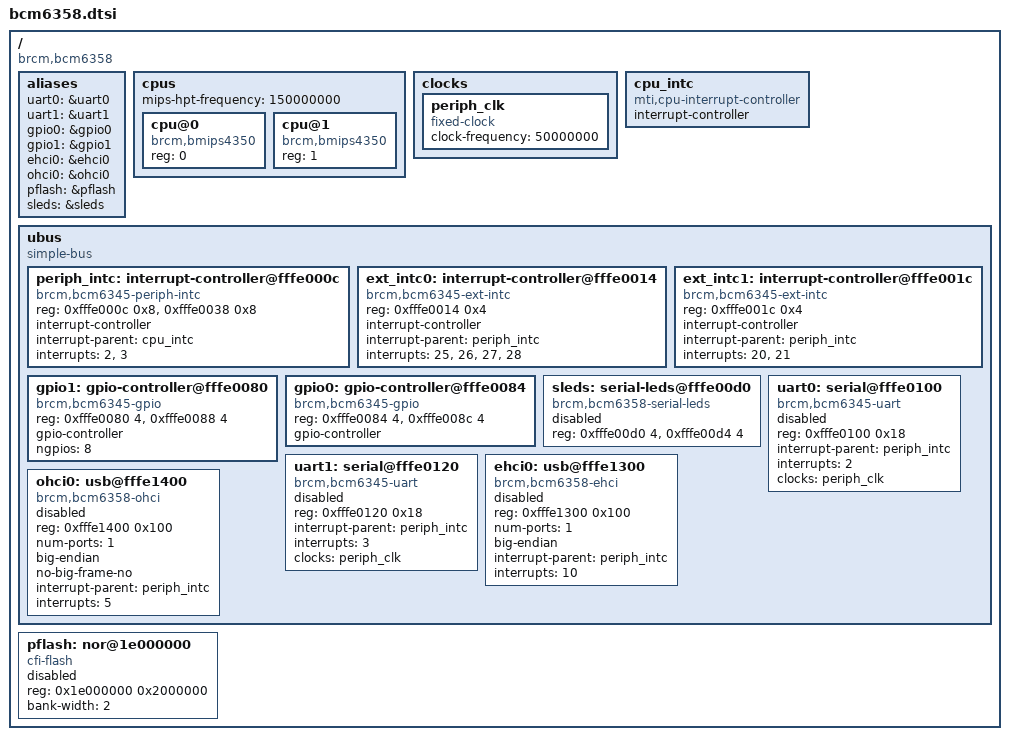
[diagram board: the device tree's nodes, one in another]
/ {
	#address-cells = <1>;
	#size-cells = <1>;
	compatible = "brcm,bcm6358";

	aliases {
		uart0 = &uart0;
		uart1 = &uart1;
		gpio0 = &gpio0;
		gpio1 = &gpio1;
		ehci0 = &ehci0;
		ohci0 = &ohci0;
		pflash = &pflash;
		sleds = &sleds;
	};

	cpus {
		#address-cells = <1>;
		#size-cells = <0>;

		mips-hpt-frequency = <150000000>;

		cpu@0 {
			compatible = "brcm,bmips4350";
			device_type = "cpu";
			reg = <0>;
		};

		cpu@1 {
			compatible = "brcm,bmips4350";
			device_type = "cpu";
			reg = <1>;
		};
	};

	clocks {
		periph_clk: periph_clk {
			compatible = "fixed-clock";
			#clock-cells = <0>;
			clock-frequency = <50000000>;
		};
	};

	cpu_intc: cpu_intc {
		#address-cells = <0>;
		compatible = "mti,cpu-interrupt-controller";

		interrupt-controller;
		#interrupt-cells = <1>;
	};

	ubus {
		#address-cells = <1>;
		#size-cells = <1>;

		compatible = "simple-bus";
		ranges;

		periph_intc: interrupt-controller@fffe000c {
			compatible = "brcm,bcm6345-periph-intc";
			reg = <0xfffe000c 0x8>,
			      <0xfffe0038 0x8>;

			interrupt-controller;
			#interrupt-cells = <1>;

			interrupt-parent = <&cpu_intc>;
			interrupts = <2>, <3>;
		};

		ext_intc0: interrupt-controller@fffe0014 {
			compatible = "brcm,bcm6345-ext-intc";
			reg = <0xfffe0014 0x4>;

			interrupt-controller;
			#interrupt-cells = <2>;

			interrupt-parent = <&periph_intc>;
			interrupts = <25>, <26>, <27>, <28>;
		};

		ext_intc1: interrupt-controller@fffe001c {
			compatible = "brcm,bcm6345-ext-intc";
			reg = <0xfffe001c 0x4>;

			interrupt-controller;
			#interrupt-cells = <2>;

			interrupt-parent = <&periph_intc>;
			interrupts = <20>, <21>;
		};

		gpio1: gpio-controller@fffe0080 {
			compatible = "brcm,bcm6345-gpio";
			reg = <0xfffe0080 4>, <0xfffe0088 4>;

			gpio-controller;
			#gpio-cells = <2>;

			ngpios = <8>;
		};

		gpio0: gpio-controller@fffe0084 {
			compatible = "brcm,bcm6345-gpio";
			reg = <0xfffe0084 4>, <0xfffe008c 4>;

			gpio-controller;
			#gpio-cells = <2>;
		};

		sleds: serial-leds@fffe00d0 {
			compatible = "brcm,bcm6358-serial-leds";
			reg = <0xfffe00d0 4>, <0xfffe00d4 4>;
			reg-names = "dat", "ctl";

			status = "disabled";
		};

		uart0: serial@fffe0100 {
			compatible = "brcm,bcm6345-uart";
			reg = <0xfffe0100 0x18>;
			interrupt-parent = <&periph_intc>;
			interrupts = <2>;
			clocks = <&periph_clk>;
			status = "disabled";
		};

		uart1: serial@fffe0120 {
			compatible = "brcm,bcm6345-uart";
			reg = <0xfffe0120 0x18>;
			interrupt-parent = <&periph_intc>;
			interrupts = <3>;
			clocks = <&periph_clk>;
			status = "disabled";
		};

		ehci0: usb@fffe1300 {
			compatible = "brcm,bcm6358-ehci", "generic-ehci";
			reg = <0xfffe1300 0x100>;
			num-ports = <1>;
			big-endian;
			interrupt-parent = <&periph_intc>;
			interrupts = <10>;
			status = "disabled";
		};

		ohci0: usb@fffe1400 {
			compatible = "brcm,bcm6358-ohci", "generic-ohci";
			reg = <0xfffe1400 0x100>;
			num-ports = <1>;
			big-endian;
			no-big-frame-no;
			interrupt-parent = <&periph_intc>;
			interrupts = <5>;
			status = "disabled";
		};
	};

	pflash: nor@1e000000 {
		compatible = "cfi-flash";
		reg = <0x1e000000 0x2000000>;
		bank-width = <2>;
		#address-cells = <1>;
		#size-cells = <1>;
		status = "disabled";
	};
};
